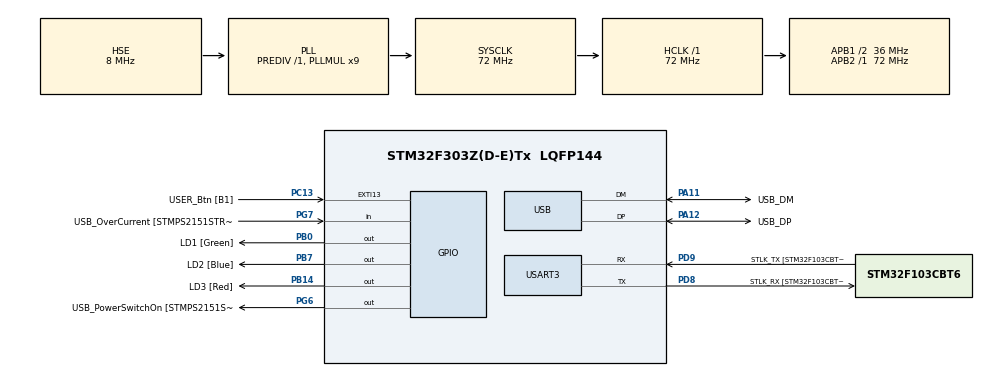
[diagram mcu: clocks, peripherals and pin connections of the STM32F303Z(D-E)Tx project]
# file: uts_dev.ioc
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FREERTOS.INCLUDE_pcTaskGetTaskName=1
FREERTOS.INCLUDE_vTaskDelete=0
FREERTOS.INCLUDE_xEventGroupSetBitFromISR=1
FREERTOS.Tasks01=defaultTask,24,256,StartDefaultTask,Default,NULL,Dynamic,NULL,NULL;usbCOMportTask,8,512,usbCOMStartTask,Default,NULL,Dynamic,NULL,NULL
FREERTOS.configMINIMAL_STACK_SIZE=256
FREERTOS.configTOTAL_HEAP_SIZE=6000
FREERTOS.configUSE_TICKLESS_IDLE=2
Mcu.Family=STM32F3
Mcu.Name=STM32F303Z(D-E)Tx
Mcu.Package=LQFP144
NVIC.PriorityGroup=NVIC_PRIORITYGROUP_4
NVIC.TIM8_UP_IRQn=true\:0\:0\:false\:false\:true\:false\:false\:true
NVIC.TimeBase=TIM8_UP_IRQn
NVIC.TimeBaseIP=TIM8
NVIC.USB_LP_CAN_RX0_IRQn=true\:5\:0\:false\:false\:true\:true\:true\:true
PA11.GPIO_Label=USB_DM
PA11.Mode=Device
PA11.Signal=USB_DM
PA12.GPIO_Label=USB_DP
PA12.Mode=Device
PA12.Signal=USB_DP
PA13.GPIO_Label=TMS
PA13.Mode=Serial_Wire
PA13.Signal=SYS_JTMS-SWDIO
PA14.GPIO_Label=TCK
PA14.Mode=Serial_Wire
PA14.Signal=SYS_JTCK-SWCLK
PB0.GPIO_Label=LD1 [Green]
PB0.Signal=GPIO_Output
PB14.GPIO_Label=LD3 [Red]
PB14.Signal=GPIO_Output
PB3.GPIO_Label=SWO
PB3.Signal=SYS_JTDO-TRACESWO
PB7.GPIO_Label=LD2 [Blue]
PB7.Signal=GPIO_Output
PC13.GPIO_Label=USER_Btn [B1]
PC13.Signal=GPXTI13
PC14-OSC32_IN.Mode=LSE-External-Oscillator
PC14-OSC32_IN.Signal=RCC_OSC32_IN
PC15-OSC32_OUT.Mode=LSE-External-Oscillator
PC15-OSC32_OUT.Signal=RCC_OSC32_OUT
PD8.GPIO_Label=STLK_RX [STM32F103CBT6_PA3]
PD8.Mode=Asynchronous
PD8.Signal=USART3_TX
PD9.GPIO_Label=STLK_TX [STM32F103CBT6_PA2]
PD9.Mode=Asynchronous
PD9.Signal=USART3_RX
PF0-OSC_IN.GPIO_Label=MCO [STM32F103CBT6_PA8]
PF0-OSC_IN.Mode=HSE-External-Clock-Source
PF0-OSC_IN.Signal=RCC_OSC_IN
PG6.GPIO_Label=USB_PowerSwitchOn [STMPS2151STR_EN]
PG6.Signal=GPIO_Output
PG7.GPIO_Label=USB_OverCurrent [STMPS2151STR_FAULT]
PG7.Signal=GPIO_Input
ProjectManager.HeapSize=0x200
ProjectManager.StackSize=0x400
ProjectManager.TargetToolchain=STM32CubeIDE
RCC.AHBFreq_Value=72000000
RCC.APB1CLKDivider=RCC_HCLK_DIV2
RCC.APB1Freq_Value=36000000
RCC.APB1TimFreq_Value=72000000
RCC.APB2Freq_Value=72000000
RCC.APB2TimFreq_Value=72000000
RCC.CortexFreq_Value=72000000
RCC.HCLKFreq_Value=72000000
RCC.HSE_VALUE=8000000
RCC.HSI_VALUE=8000000
RCC.PLLMUL=RCC_PLL_MUL9
RCC.PRESCALERUSB=RCC_USBCLKSOURCE_PLL_DIV1_5
RCC.SYSCLKFreq_VALUE=72000000
RCC.SYSCLKSourceVirtual=RCC_SYSCLKSOURCE_PLLCLK
RCC.USBFreq_Value=48000000
USART3.VirtualMode-Asynchronous=VM_ASYNC
USB_DEVICE.CLASS_NAME_FS=CDC
USB_DEVICE.VirtualMode=Cdc
USB_DEVICE.VirtualModeFS=Cdc_FS
VP_FREERTOS_VS_CMSIS_V2.Mode=CMSIS_V2
VP_RTC_VS_RTC_Activate.Mode=RTC_Enabled
VP_SYS_VS_tim8.Mode=TIM8
VP_USB_DEVICE_VS_USB_DEVICE_CDC_FS.Mode=CDC_FS
board=NUCLEO-F303ZE

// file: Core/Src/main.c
/* USER CODE BEGIN Header */
/**
  ******************************************************************************
  * @file           : main.c
  * @brief          : Main program body
  ******************************************************************************
  * @attention
  *
  * <h2><center>&copy; Copyright (c) 2019 STMicroelectronics.
  * All rights reserved.</center></h2>
  *
  * This software component is licensed by ST under BSD 3-Clause license,
  * the "License"; You may not use this file except in compliance with the
  * License. You may obtain a copy of the License at:
  *                        opensource.org/licenses/BSD-3-Clause
  *
  ******************************************************************************
  */
/* USER CODE END Header */

#include "main.h"
#include "cmsis_os.h"
#include "usb_device.h"

RTC_HandleTypeDef hrtc;

UART_HandleTypeDef huart3;

osThreadId_t defaultTaskHandle;
osThreadId_t usbCOMportTaskHandle;

void SystemClock_Config(void);
static void MX_GPIO_Init(void);
static void MX_RTC_Init(void);
static void MX_USART3_UART_Init(void);
void StartDefaultTask(void *argument);
void usbCOMStartTask(void *argument);

int main(void)
{

  /* MCU Configuration--------------------------------------------------------*/

  /* Reset of all peripherals, Initializes the Flash interface and the Systick. */
  HAL_Init();

  /* Configure the system clock */
  SystemClock_Config();

  /* Initialize all configured peripherals */
  MX_GPIO_Init();
  MX_RTC_Init();
  MX_USART3_UART_Init();

  osKernelInitialize();

  /* Create the thread(s) */
  /* definition and creation of defaultTask */
  const osThreadAttr_t defaultTask_attributes = {
    .name = "defaultTask",
    .priority = (osPriority_t) osPriorityNormal,
    .stack_size = 256
  };
  defaultTaskHandle = osThreadNew(StartDefaultTask, NULL, &defaultTask_attributes);

  /* definition and creation of usbCOMportTask */
  const osThreadAttr_t usbCOMportTask_attributes = {
    .name = "usbCOMportTask",
    .priority = (osPriority_t) osPriorityLow,
    .stack_size = 512
  };
  usbCOMportTaskHandle = osThreadNew(usbCOMStartTask, NULL, &usbCOMportTask_attributes);

  /* Start scheduler */
  osKernelStart();

  /* We should never get here as control is now taken by the scheduler */

  /* Infinite loop */
  while (1)
  {

  }
}

void SystemClock_Config(void)
{
  RCC_OscInitTypeDef RCC_OscInitStruct = {0};
  RCC_ClkInitTypeDef RCC_ClkInitStruct = {0};
  RCC_PeriphCLKInitTypeDef PeriphClkInit = {0};

  /** Initializes the CPU, AHB and APB busses clocks
  */
  RCC_OscInitStruct.OscillatorType = RCC_OSCILLATORTYPE_LSI|RCC_OSCILLATORTYPE_HSE;
  RCC_OscInitStruct.HSEState = RCC_HSE_BYPASS;
  RCC_OscInitStruct.HSIState = RCC_HSI_ON;
  RCC_OscInitStruct.LSIState = RCC_LSI_ON;
  RCC_OscInitStruct.PLL.PLLState = RCC_PLL_ON;
  RCC_OscInitStruct.PLL.PLLSource = RCC_PLLSOURCE_HSE;
  RCC_OscInitStruct.PLL.PLLMUL = RCC_PLL_MUL9;
  RCC_OscInitStruct.PLL.PREDIV = RCC_PREDIV_DIV1;
  if (HAL_RCC_OscConfig(&RCC_OscInitStruct) != HAL_OK)
  {
    Error_Handler();
  }
  /** Initializes the CPU, AHB and APB busses clocks
  */
  RCC_ClkInitStruct.ClockType = RCC_CLOCKTYPE_HCLK|RCC_CLOCKTYPE_SYSCLK
                              |RCC_CLOCKTYPE_PCLK1|RCC_CLOCKTYPE_PCLK2;
  RCC_ClkInitStruct.SYSCLKSource = RCC_SYSCLKSOURCE_PLLCLK;
  RCC_ClkInitStruct.AHBCLKDivider = RCC_SYSCLK_DIV1;
  RCC_ClkInitStruct.APB1CLKDivider = RCC_HCLK_DIV2;
  RCC_ClkInitStruct.APB2CLKDivider = RCC_HCLK_DIV1;

  if (HAL_RCC_ClockConfig(&RCC_ClkInitStruct, FLASH_LATENCY_2) != HAL_OK)
  {
    Error_Handler();
  }
  PeriphClkInit.PeriphClockSelection = RCC_PERIPHCLK_USB|RCC_PERIPHCLK_USART3
                              |RCC_PERIPHCLK_RTC;
  PeriphClkInit.Usart3ClockSelection = RCC_USART3CLKSOURCE_PCLK1;
  PeriphClkInit.RTCClockSelection = RCC_RTCCLKSOURCE_LSI;
  PeriphClkInit.USBClockSelection = RCC_USBCLKSOURCE_PLL_DIV1_5;
  if (HAL_RCCEx_PeriphCLKConfig(&PeriphClkInit) != HAL_OK)
  {
    Error_Handler();
  }
}

static void MX_RTC_Init(void)
{

  /** Initialize RTC Only
  */
  hrtc.Instance = RTC;
  hrtc.Init.HourFormat = RTC_HOURFORMAT_24;
  hrtc.Init.AsynchPrediv = 127;
  hrtc.Init.SynchPrediv = 255;
  hrtc.Init.OutPut = RTC_OUTPUT_DISABLE;
  hrtc.Init.OutPutPolarity = RTC_OUTPUT_POLARITY_HIGH;
  hrtc.Init.OutPutType = RTC_OUTPUT_TYPE_OPENDRAIN;
  if (HAL_RTC_Init(&hrtc) != HAL_OK)
  {
    Error_Handler();
  }

}

static void MX_USART3_UART_Init(void)
{

  huart3.Instance = USART3;
  huart3.Init.BaudRate = 38400;
  huart3.Init.WordLength = UART_WORDLENGTH_8B;
  huart3.Init.StopBits = UART_STOPBITS_1;
  huart3.Init.Parity = UART_PARITY_NONE;
  huart3.Init.Mode = UART_MODE_TX_RX;
  huart3.Init.HwFlowCtl = UART_HWCONTROL_NONE;
  huart3.Init.OverSampling = UART_OVERSAMPLING_16;
  huart3.Init.OneBitSampling = UART_ONE_BIT_SAMPLE_DISABLE;
  huart3.AdvancedInit.AdvFeatureInit = UART_ADVFEATURE_NO_INIT;
  if (HAL_UART_Init(&huart3) != HAL_OK)
  {
    Error_Handler();
  }

}

static void MX_GPIO_Init(void)
{
  GPIO_InitTypeDef GPIO_InitStruct = {0};

  /* GPIO Ports Clock Enable */
  __HAL_RCC_GPIOC_CLK_ENABLE();
  __HAL_RCC_GPIOF_CLK_ENABLE();
  __HAL_RCC_GPIOB_CLK_ENABLE();
  __HAL_RCC_GPIOD_CLK_ENABLE();
  __HAL_RCC_GPIOG_CLK_ENABLE();
  __HAL_RCC_GPIOA_CLK_ENABLE();

  /*Configure GPIO pin Output Level */
  HAL_GPIO_WritePin(GPIOB, LD1_Pin|LD3_Pin|LD2_Pin, GPIO_PIN_RESET);

  /*Configure GPIO pin Output Level */
  HAL_GPIO_WritePin(USB_PowerSwitchOn_GPIO_Port, USB_PowerSwitchOn_Pin, GPIO_PIN_RESET);

  /*Configure GPIO pin : USER_Btn_Pin */
  GPIO_InitStruct.Pin = USER_Btn_Pin;
  GPIO_InitStruct.Mode = GPIO_MODE_IT_RISING;
  GPIO_InitStruct.Pull = GPIO_NOPULL;
  HAL_GPIO_Init(USER_Btn_GPIO_Port, &GPIO_InitStruct);

  /*Configure GPIO pins : LD1_Pin LD3_Pin LD2_Pin */
  GPIO_InitStruct.Pin = LD1_Pin|LD3_Pin|LD2_Pin;
  GPIO_InitStruct.Mode = GPIO_MODE_OUTPUT_PP;
  GPIO_InitStruct.Pull = GPIO_NOPULL;
  GPIO_InitStruct.Speed = GPIO_SPEED_FREQ_LOW;
  HAL_GPIO_Init(GPIOB, &GPIO_InitStruct);

  /*Configure GPIO pin : USB_PowerSwitchOn_Pin */
  GPIO_InitStruct.Pin = USB_PowerSwitchOn_Pin;
  GPIO_InitStruct.Mode = GPIO_MODE_OUTPUT_PP;
  GPIO_InitStruct.Pull = GPIO_NOPULL;
  GPIO_InitStruct.Speed = GPIO_SPEED_FREQ_LOW;
  HAL_GPIO_Init(USB_PowerSwitchOn_GPIO_Port, &GPIO_InitStruct);

  /*Configure GPIO pin : USB_OverCurrent_Pin */
  GPIO_InitStruct.Pin = USB_OverCurrent_Pin;
  GPIO_InitStruct.Mode = GPIO_MODE_INPUT;
  GPIO_InitStruct.Pull = GPIO_NOPULL;
  HAL_GPIO_Init(USB_OverCurrent_GPIO_Port, &GPIO_InitStruct);

}

void StartDefaultTask(void *argument)
{
  /* init code for USB_DEVICE */
  MX_USB_DEVICE_Init();
  /* USER CODE BEGIN 5 */
  /* Infinite loop */
  for(;;)
  {
		HAL_GPIO_WritePin(GPIOB, LD3_Pin|LD2_Pin, GPIO_PIN_RESET);
		osDelay(500);
		HAL_GPIO_WritePin(GPIOB, LD3_Pin|LD2_Pin, GPIO_PIN_SET);
		osDelay(500);
  }
  /* USER CODE END 5 */
}

void usbCOMStartTask(void *argument)
{
  /* USER CODE BEGIN usbCOMStartTask */
  /* Infinite loop */
	HAL_Delay(2000);
	HAL_GPIO_WritePin(USB_PowerSwitchOn_GPIO_Port, USB_PowerSwitchOn_Pin, GPIO_PIN_SET);

	uint8_t tr_data[8] = {0x42, 0x00, 0x00, 0x00, 0x00, 0x00, 0x00, 0x00};
  for(;;)
  {
	  CDC_Transmit_FS(tr_data, 8);
    osDelay(1000);
  }
  /* USER CODE END usbCOMStartTask */
}

void HAL_TIM_PeriodElapsedCallback(TIM_HandleTypeDef *htim)
{
  if (htim->Instance == TIM8) {
    HAL_IncTick();
  }
}

void Error_Handler(void)
{
}

/************************ (C) COPYRIGHT STMicroelectronics *****END OF FILE****/

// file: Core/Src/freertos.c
/* USER CODE BEGIN Header */
/**
  ******************************************************************************
  * File Name          : freertos.c
  * Description        : Code for freertos applications
  ******************************************************************************
  * @attention
  *
  * <h2><center>&copy; Copyright (c) 2019 STMicroelectronics.
  * All rights reserved.</center></h2>
  *
  * This software component is licensed by ST under Ultimate Liberty license
  * SLA0044, the "License"; You may not use this file except in compliance with
  * the License. You may obtain a copy of the License at:
  *                             www.st.com/SLA0044
  *
  ******************************************************************************
  */
/* USER CODE END Header */

#include "FreeRTOS.h"
#include "task.h"
#include "main.h"

/* USER CODE BEGIN VPORT_SUPPORT_TICKS_AND_SLEEP */
__weak void vPortSuppressTicksAndSleep( TickType_t xExpectedIdleTime )
{
  // Generated when configUSE_TICKLESS_IDLE == 2.
  // Function called in tasks.c (in portTASK_FUNCTION).
  // TO BE COMPLETED or TO BE REPLACED by a user one, overriding that weak one.
}
/* USER CODE END VPORT_SUPPORT_TICKS_AND_SLEEP */

/************************ (C) COPYRIGHT STMicroelectronics *****END OF FILE****/
